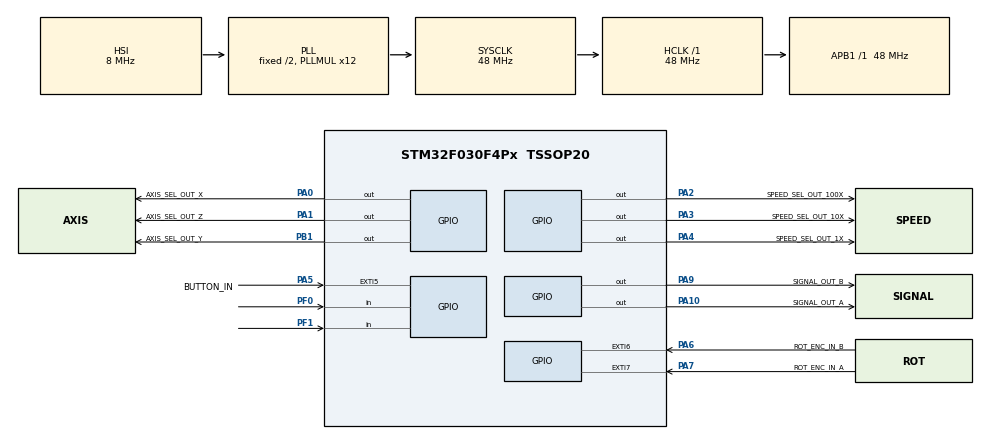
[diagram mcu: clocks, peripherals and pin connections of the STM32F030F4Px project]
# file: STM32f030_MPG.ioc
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Mcu.Family=STM32F0
Mcu.Name=STM32F030F4Px
Mcu.Package=TSSOP20
NVIC.EXTI4_15_IRQn=true\:0\:0\:false\:false\:true\:true\:true
NVIC.TIM1_BRK_UP_TRG_COM_IRQn=true\:0\:0\:false\:false\:true\:true\:true
NVIC.TIM1_CC_IRQn=true\:0\:0\:false\:false\:true\:true\:true
NVIC.TIM3_IRQn=true\:0\:0\:false\:false\:true\:true\:true
PA0.GPIO_Label=AXIS_SEL_OUT_X
PA0.Signal=GPIO_Output
PA1.GPIO_Label=AXIS_SEL_OUT_Z
PA1.Signal=GPIO_Output
PA10.GPIO_Label=SIGNAL_OUT_A
PA10.GPIO_ModeDefaultOutputPP=GPIO_MODE_OUTPUT_PP
PA10.GPIO_PuPd=GPIO_NOPULL
PA10.Signal=GPIO_Output
PA13.Mode=Serial_Wire
PA13.Signal=SYS_SWDIO
PA14.Mode=Serial_Wire
PA14.Signal=SYS_SWCLK
PA2.GPIO_Label=SPEED_SEL_OUT_100X
PA2.Signal=GPIO_Output
PA3.GPIO_Label=SPEED_SEL_OUT_10X
PA3.Signal=GPIO_Output
PA4.GPIO_Label=SPEED_SEL_OUT_1X
PA4.Signal=GPIO_Output
PA5.GPIO_Label=BUTTON_IN
PA5.GPIO_ModeDefaultEXTI=GPIO_MODE_IT_FALLING
PA5.GPIO_PuPd=GPIO_PULLUP
PA5.Signal=GPXTI5
PA6.GPIO_Label=ROT_ENC_IN_B
PA6.GPIO_PuPd=GPIO_PULLUP
PA6.Signal=GPXTI6
PA7.GPIO_Label=ROT_ENC_IN_A
PA7.GPIO_ModeDefaultEXTI=GPIO_MODE_IT_RISING
PA7.GPIO_PuPd=GPIO_PULLUP
PA7.Signal=GPXTI7
PA9.GPIO_Label=SIGNAL_OUT_B
PA9.GPIO_ModeDefaultOutputPP=GPIO_MODE_OUTPUT_PP
PA9.GPIO_PuPd=GPIO_NOPULL
PA9.GPIO_Speed=GPIO_SPEED_FREQ_LOW
PA9.Signal=GPIO_Output
PB1.GPIO_Label=AXIS_SEL_OUT_Y
PB1.GPIO_ModeDefaultOutputPP=GPIO_MODE_OUTPUT_OD
PB1.Signal=GPIO_Output
PF0-OSC_IN.Signal=GPIO_Input
PF1-OSC_OUT.Signal=GPIO_Input
ProjectManager.HeapSize=0x200
ProjectManager.StackSize=0x400
ProjectManager.TargetToolchain=STM32CubeIDE
RCC.AHBFreq_Value=48000000
RCC.APB1Freq_Value=48000000
RCC.APB1TimFreq_Value=48000000
RCC.HCLKFreq_Value=48000000
RCC.PLLMUL=RCC_PLL_MUL12
RCC.SYSCLKFreq_VALUE=48000000
RCC.SYSCLKSource=RCC_SYSCLKSOURCE_PLLCLK
TIM1.Period=50
TIM1.Prescaler=48000
TIM1.TIM_MasterOutputTrigger=TIM_TRGO_ENABLE
TIM3.Period=99
TIM3.Prescaler=48
TIM3.TIM_MasterOutputTrigger=TIM_TRGO_ENABLE
VP_TIM1_VS_ClockSourceINT.Mode=Internal
VP_TIM3_VS_ClockSourceINT.Mode=Internal
board=custom

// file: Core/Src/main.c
/* USER CODE BEGIN Header */
/**
  ******************************************************************************
  * @file           : main.c
  * @brief          : Main program body
  ******************************************************************************
  * @attention
  *
  * Copyright (c) 2024 STMicroelectronics.
  * All rights reserved.
  *
  * This software is licensed under terms that can be found in the LICENSE file
  * in the root directory of this software component.
  * If no LICENSE file comes with this software, it is provided AS-IS.
  *
  ******************************************************************************
  */
/* USER CODE END Header */
#include "main.h"

/* USER CODE BEGIN PTD */
void app_main(void);
void app_setup(void);
/* USER CODE END PTD */

TIM_HandleTypeDef htim1;
TIM_HandleTypeDef htim3;

void SystemClock_Config(void);
static void MX_GPIO_Init(void);
static void MX_TIM1_Init(void);
static void MX_TIM3_Init(void);

int main(void)
{

  /* MCU Configuration--------------------------------------------------------*/

  /* Reset of all peripherals, Initializes the Flash interface and the Systick. */
  HAL_Init();

  /* Configure the system clock */
  SystemClock_Config();

  /* Initialize all configured peripherals */
  MX_GPIO_Init();
  MX_TIM1_Init();
  MX_TIM3_Init();
  /* USER CODE BEGIN 2 */
   app_setup();
  /* USER CODE END 2 */

  /* Infinite loop */
  /* USER CODE BEGIN WHILE */
  while (1)
  {
	  app_main();
    /* USER CODE END WHILE */

  }
}

void SystemClock_Config(void)
{
  RCC_OscInitTypeDef RCC_OscInitStruct = {0};
  RCC_ClkInitTypeDef RCC_ClkInitStruct = {0};

  /** Initializes the RCC Oscillators according to the specified parameters
  * in the RCC_OscInitTypeDef structure.
  */
  RCC_OscInitStruct.OscillatorType = RCC_OSCILLATORTYPE_HSI;
  RCC_OscInitStruct.HSIState = RCC_HSI_ON;
  RCC_OscInitStruct.HSICalibrationValue = RCC_HSICALIBRATION_DEFAULT;
  RCC_OscInitStruct.PLL.PLLState = RCC_PLL_ON;
  RCC_OscInitStruct.PLL.PLLSource = RCC_PLLSOURCE_HSI;
  RCC_OscInitStruct.PLL.PLLMUL = RCC_PLL_MUL12;
  RCC_OscInitStruct.PLL.PREDIV = RCC_PREDIV_DIV1;
  if (HAL_RCC_OscConfig(&RCC_OscInitStruct) != HAL_OK)
  {
    Error_Handler();
  }
  /** Initializes the CPU, AHB and APB buses clocks
  */
  RCC_ClkInitStruct.ClockType = RCC_CLOCKTYPE_HCLK|RCC_CLOCKTYPE_SYSCLK
                              |RCC_CLOCKTYPE_PCLK1;
  RCC_ClkInitStruct.SYSCLKSource = RCC_SYSCLKSOURCE_PLLCLK;
  RCC_ClkInitStruct.AHBCLKDivider = RCC_SYSCLK_DIV1;
  RCC_ClkInitStruct.APB1CLKDivider = RCC_HCLK_DIV1;

  if (HAL_RCC_ClockConfig(&RCC_ClkInitStruct, FLASH_LATENCY_1) != HAL_OK)
  {
    Error_Handler();
  }
}

static void MX_TIM1_Init(void)
{

  TIM_ClockConfigTypeDef sClockSourceConfig = {0};
  TIM_MasterConfigTypeDef sMasterConfig = {0};

  htim1.Instance = TIM1;
  htim1.Init.Prescaler = 48000;
  htim1.Init.CounterMode = TIM_COUNTERMODE_UP;
  htim1.Init.Period = 50;
  htim1.Init.ClockDivision = TIM_CLOCKDIVISION_DIV1;
  htim1.Init.RepetitionCounter = 0;
  htim1.Init.AutoReloadPreload = TIM_AUTORELOAD_PRELOAD_DISABLE;
  if (HAL_TIM_Base_Init(&htim1) != HAL_OK)
  {
    Error_Handler();
  }
  sClockSourceConfig.ClockSource = TIM_CLOCKSOURCE_INTERNAL;
  if (HAL_TIM_ConfigClockSource(&htim1, &sClockSourceConfig) != HAL_OK)
  {
    Error_Handler();
  }
  sMasterConfig.MasterOutputTrigger = TIM_TRGO_ENABLE;
  sMasterConfig.MasterSlaveMode = TIM_MASTERSLAVEMODE_DISABLE;
  if (HAL_TIMEx_MasterConfigSynchronization(&htim1, &sMasterConfig) != HAL_OK)
  {
    Error_Handler();
  }

}

static void MX_TIM3_Init(void)
{

  TIM_ClockConfigTypeDef sClockSourceConfig = {0};
  TIM_MasterConfigTypeDef sMasterConfig = {0};

  htim3.Instance = TIM3;
  htim3.Init.Prescaler = 48;
  htim3.Init.CounterMode = TIM_COUNTERMODE_UP;
  htim3.Init.Period = 99;
  htim3.Init.ClockDivision = TIM_CLOCKDIVISION_DIV1;
  htim3.Init.AutoReloadPreload = TIM_AUTORELOAD_PRELOAD_DISABLE;
  if (HAL_TIM_Base_Init(&htim3) != HAL_OK)
  {
    Error_Handler();
  }
  sClockSourceConfig.ClockSource = TIM_CLOCKSOURCE_INTERNAL;
  if (HAL_TIM_ConfigClockSource(&htim3, &sClockSourceConfig) != HAL_OK)
  {
    Error_Handler();
  }
  sMasterConfig.MasterOutputTrigger = TIM_TRGO_ENABLE;
  sMasterConfig.MasterSlaveMode = TIM_MASTERSLAVEMODE_DISABLE;
  if (HAL_TIMEx_MasterConfigSynchronization(&htim3, &sMasterConfig) != HAL_OK)
  {
    Error_Handler();
  }

}

static void MX_GPIO_Init(void)
{
  GPIO_InitTypeDef GPIO_InitStruct = {0};

  /* GPIO Ports Clock Enable */
  __HAL_RCC_GPIOF_CLK_ENABLE();
  __HAL_RCC_GPIOA_CLK_ENABLE();
  __HAL_RCC_GPIOB_CLK_ENABLE();

  /*Configure GPIO pin Output Level */
  HAL_GPIO_WritePin(GPIOA, AXIS_SEL_OUT_X_Pin|AXIS_SEL_OUT_Z_Pin|SPEED_SEL_OUT_100X_Pin|SPEED_SEL_OUT_10X_Pin
                          |SPEED_SEL_OUT_1X_Pin|SIGNAL_OUT_B_Pin|SIGNAL_OUT_A_Pin, GPIO_PIN_RESET);

  /*Configure GPIO pin Output Level */
  HAL_GPIO_WritePin(AXIS_SEL_OUT_Y_GPIO_Port, AXIS_SEL_OUT_Y_Pin, GPIO_PIN_RESET);

  /*Configure GPIO pins : PF0 PF1 */
  GPIO_InitStruct.Pin = GPIO_PIN_0|GPIO_PIN_1;
  GPIO_InitStruct.Mode = GPIO_MODE_INPUT;
  GPIO_InitStruct.Pull = GPIO_NOPULL;
  HAL_GPIO_Init(GPIOF, &GPIO_InitStruct);

  /*Configure GPIO pins : AXIS_SEL_OUT_X_Pin AXIS_SEL_OUT_Z_Pin SPEED_SEL_OUT_100X_Pin SPEED_SEL_OUT_10X_Pin
                           SPEED_SEL_OUT_1X_Pin SIGNAL_OUT_B_Pin SIGNAL_OUT_A_Pin */
  GPIO_InitStruct.Pin = AXIS_SEL_OUT_X_Pin|AXIS_SEL_OUT_Z_Pin|SPEED_SEL_OUT_100X_Pin|SPEED_SEL_OUT_10X_Pin
                          |SPEED_SEL_OUT_1X_Pin|SIGNAL_OUT_B_Pin|SIGNAL_OUT_A_Pin;
  GPIO_InitStruct.Mode = GPIO_MODE_OUTPUT_PP;
  GPIO_InitStruct.Pull = GPIO_NOPULL;
  GPIO_InitStruct.Speed = GPIO_SPEED_FREQ_LOW;
  HAL_GPIO_Init(GPIOA, &GPIO_InitStruct);

  /*Configure GPIO pin : BUTTON_IN_Pin */
  GPIO_InitStruct.Pin = BUTTON_IN_Pin;
  GPIO_InitStruct.Mode = GPIO_MODE_IT_FALLING;
  GPIO_InitStruct.Pull = GPIO_PULLUP;
  HAL_GPIO_Init(BUTTON_IN_GPIO_Port, &GPIO_InitStruct);

  /*Configure GPIO pins : ROT_ENC_IN_B_Pin ROT_ENC_IN_A_Pin */
  GPIO_InitStruct.Pin = ROT_ENC_IN_B_Pin|ROT_ENC_IN_A_Pin;
  GPIO_InitStruct.Mode = GPIO_MODE_IT_RISING;
  GPIO_InitStruct.Pull = GPIO_PULLUP;
  HAL_GPIO_Init(GPIOA, &GPIO_InitStruct);

  /*Configure GPIO pin : AXIS_SEL_OUT_Y_Pin */
  GPIO_InitStruct.Pin = AXIS_SEL_OUT_Y_Pin;
  GPIO_InitStruct.Mode = GPIO_MODE_OUTPUT_OD;
  GPIO_InitStruct.Pull = GPIO_NOPULL;
  GPIO_InitStruct.Speed = GPIO_SPEED_FREQ_LOW;
  HAL_GPIO_Init(AXIS_SEL_OUT_Y_GPIO_Port, &GPIO_InitStruct);

  /* EXTI interrupt init*/
  HAL_NVIC_SetPriority(EXTI4_15_IRQn, 0, 0);
  HAL_NVIC_EnableIRQ(EXTI4_15_IRQn);

}

void Error_Handler(void)
{
  __disable_irq();
  while (1)
  {
  }
}

/************************ (C) COPYRIGHT STMicroelectronics *****END OF FILE****/
